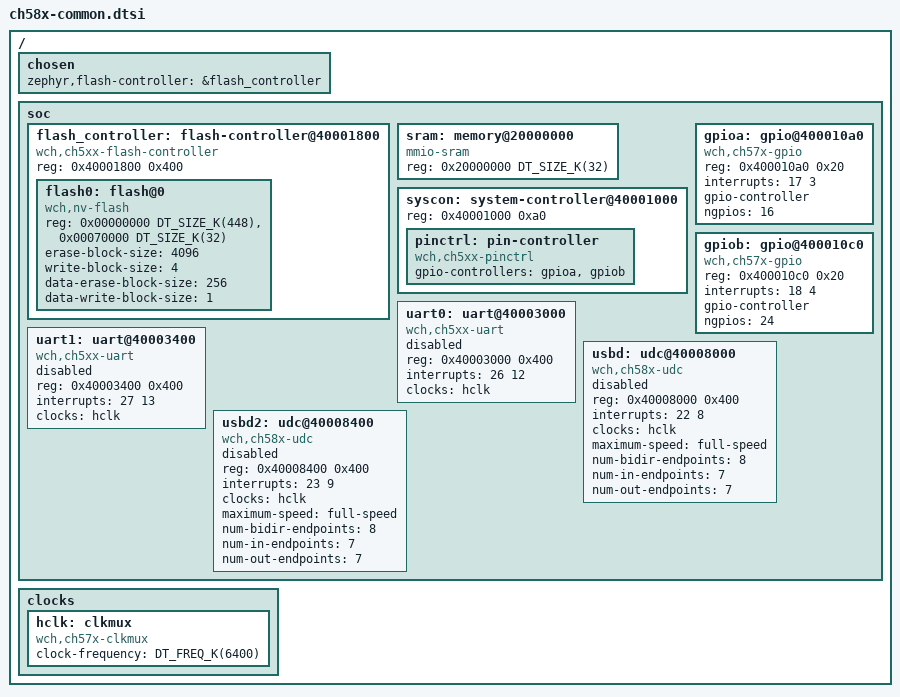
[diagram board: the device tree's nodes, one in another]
/*
 * Copyright (c) 2023-2024 Chen Xingyu <hi@xingrz.me>
 * SPDX-License-Identifier: Apache-2.0
 */

#include <mem.h>
#include <freq.h>

#include <wch/qingke-v4.dtsi>

/ {
	chosen {
		zephyr,flash-controller = &flash_controller;
	};

	soc {
		flash_controller: flash-controller@40001800 {
			compatible = "wch,ch5xx-flash-controller";
			reg = <0x40001800 0x400>;

			#address-cells = <1>;
			#size-cells = <1>;
			flash0: flash@0 {
				compatible = "wch,nv-flash", "soc-nv-flash";
				reg = <0x00000000 DT_SIZE_K(448)>,
				      <0x00070000 DT_SIZE_K(32)>;
				reg-names = "code_flash", "data_flash";
				erase-block-size = <4096>;
				write-block-size = <4>;
				data-erase-block-size = <256>;
				data-write-block-size = <1>;
			};
		};

		sram: memory@20000000 {
			compatible = "mmio-sram";
			reg = <0x20000000 DT_SIZE_K(32)>;
		};

		syscon: system-controller@40001000 {
			reg = <0x40001000 0xa0>;

			pinctrl: pin-controller {
				compatible = "wch,ch5xx-pinctrl";
				gpio-controllers = <&gpioa>, <&gpiob>;
			};
		};

		gpioa: gpio@400010a0 {
			compatible = "wch,ch57x-gpio";
			reg = <0x400010a0 0x20>;
			interrupts = <17 3>;
			gpio-controller;
			#gpio-cells = <2>;
			ngpios = <16>;
		};

		gpiob: gpio@400010c0 {
			compatible = "wch,ch57x-gpio";
			reg = <0x400010c0 0x20>;
			interrupts = <18 4>;
			gpio-controller;
			#gpio-cells = <2>;
			ngpios = <24>;
		};

		uart0: uart@40003000 {
			compatible = "wch,ch5xx-uart";
			reg = <0x40003000 0x400>;
			interrupts = <26 12>;
			clocks = <&hclk>;
			status = "disabled";
		};

		uart1: uart@40003400 {
			compatible = "wch,ch5xx-uart";
			reg = <0x40003400 0x400>;
			interrupts = <27 13>;
			clocks = <&hclk>;
			status = "disabled";
		};

		usbd: udc@40008000 {
			compatible = "wch,ch58x-udc";
			reg = <0x40008000 0x400>;
			interrupts = <22 8>;
			clocks = <&hclk>;
			maximum-speed = "full-speed";
			num-bidir-endpoints = <8>;
			num-in-endpoints = <7>;
			num-out-endpoints = <7>;
			status = "disabled";
		};

		usbd2: udc@40008400 {
			compatible = "wch,ch58x-udc";
			reg = <0x40008400 0x400>;
			interrupts = <23 9>;
			clocks = <&hclk>;
			maximum-speed = "full-speed";
			num-bidir-endpoints = <8>;
			num-in-endpoints = <7>;
			num-out-endpoints = <7>;
			status = "disabled";
		};
	};

	clocks {
		hclk: clkmux {
			compatible = "wch,ch57x-clkmux";
			clock-frequency = <DT_FREQ_K(6400)>;
			#clock-cells = <0>;
		};
	};
};
